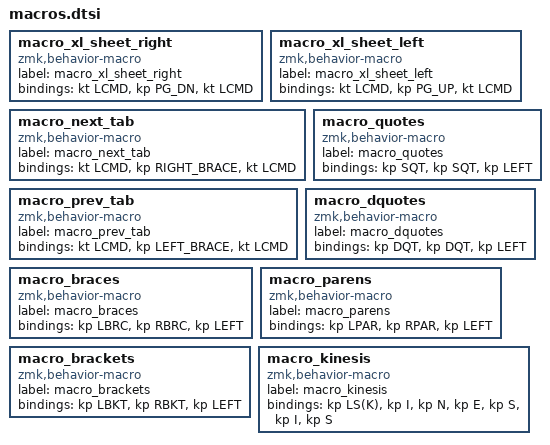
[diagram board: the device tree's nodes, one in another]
macro_xl_sheet_right: macro_xl_sheet_right{
compatible = "zmk,behavior-macro";
label = "macro_xl_sheet_right";
#binding-cells = <0>;
bindings = <&kt LCMD>, <&kp PG_DN>, <&kt LCMD>;
};
macro_xl_sheet_left: macro_xl_sheet_left{
compatible = "zmk,behavior-macro";
label = "macro_xl_sheet_left";
#binding-cells = <0>;
bindings = <&kt LCMD>, <&kp PG_UP>, <&kt LCMD>;
};
macro_next_tab: macro_next_tab{
compatible = "zmk,behavior-macro";
label = "macro_next_tab";
#binding-cells = <0>;
bindings = <&kt LCMD>, <&kp RIGHT_BRACE>, <&kt LCMD>;
};
macro_prev_tab: macro_prev_tab{
compatible = "zmk,behavior-macro";
label = "macro_prev_tab";
#binding-cells = <0>;
bindings = <&kt LCMD>, <&kp LEFT_BRACE>, <&kt LCMD>;
};
macro_quotes: macro_quotes{
compatible = "zmk,behavior-macro";
label = "macro_quotes";
#binding-cells = <0>;
bindings = <&kp SQT>, <&kp SQT>, <&kp LEFT>;
};
macro_dquotes: macro_dquotes{
compatible = "zmk,behavior-macro";
label = "macro_dquotes";
#binding-cells = <0>;
bindings = <&kp DQT>, <&kp DQT>, <&kp LEFT>;
};
macro_braces: macro_braces{
compatible = "zmk,behavior-macro";
label = "macro_braces";
#binding-cells = <0>;
bindings = <&kp LBRC>, <&kp RBRC>, <&kp LEFT>;
};
macro_parens: macro_parens{
compatible = "zmk,behavior-macro";
label = "macro_parens";
#binding-cells = <0>;
bindings = <&kp LPAR>, <&kp RPAR>, <&kp LEFT>;
};
macro_brackets: macro_brackets{
compatible = "zmk,behavior-macro";
label = "macro_brackets";
#binding-cells = <0>;
bindings = <&kp LBKT>, <&kp RBKT>, <&kp LEFT>;
};
macro_kinesis: macro_kinesis{
compatible = "zmk,behavior-macro";
label = "macro_kinesis";
#binding-cells = <0>;
bindings = <&kp LS(K)>, <&kp I>, <&kp N>, <&kp E>, <&kp S>, <&kp I>, <&kp S>;
};
